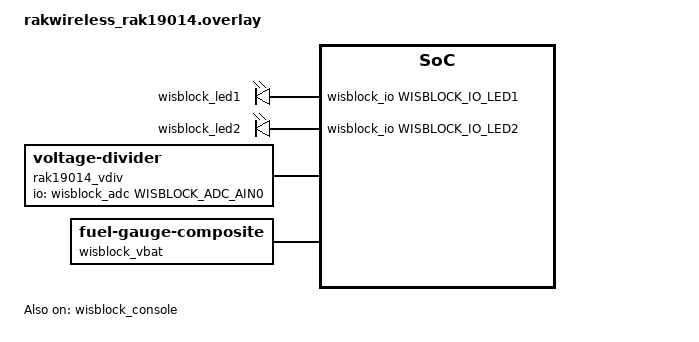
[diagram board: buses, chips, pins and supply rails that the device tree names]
/*
 * SPDX-License-Identifier: Apache-2.0
 * Copyright (c) 2026 RAKwireless Technology Limited
 */

#include <zephyr/dt-bindings/gpio/gpio.h>
#include <zephyr/dt-bindings/gpio/wisblock-io-slot.h>
#include <zephyr/dt-bindings/battery/battery.h>

/ {
	chosen {
		zephyr,console = &wisblock_console;
		zephyr,shell-uart = &wisblock_console;
		zephyr,uart-mcumgr = &wisblock_console;
		zephyr,bt-mon-uart = &wisblock_console;
		zephyr,bt-c2h-uart = &wisblock_console;
	};

	aliases {
		led0 = &wisblock_led1;
		led1 = &wisblock_led2;
		fuel-gauge0 = &wisblock_vbat;
	};

	leds {
		compatible = "gpio-leds";

		wisblock_led1: led0 {
			gpios = <&wisblock_io WISBLOCK_IO_LED1 GPIO_ACTIVE_HIGH>;
		};

		wisblock_led2: led1 {
			gpios = <&wisblock_io WISBLOCK_IO_LED2 GPIO_ACTIVE_HIGH>;
		};
	};

	rak19014_vdiv: vdiv {
		compatible = "voltage-divider";
		io-channels = <&wisblock_adc WISBLOCK_ADC_AIN0>;
		output-ohms = <1500000>;
		full-ohms = <2500000>;
	};

	wisblock_vbat: vbatt {
		compatible = "zephyr,fuel-gauge-composite";
		source-primary = <&rak19014_vdiv>;
		device-chemistry = "lithium-ion-polymer";
		ocv-capacity-table-0 =
			<BATTERY_OCV_CURVE_LITHIUM_ION_POLYMER_DEFAULT>;
	};
};

&wisblock_console {
	status = "okay";
};
